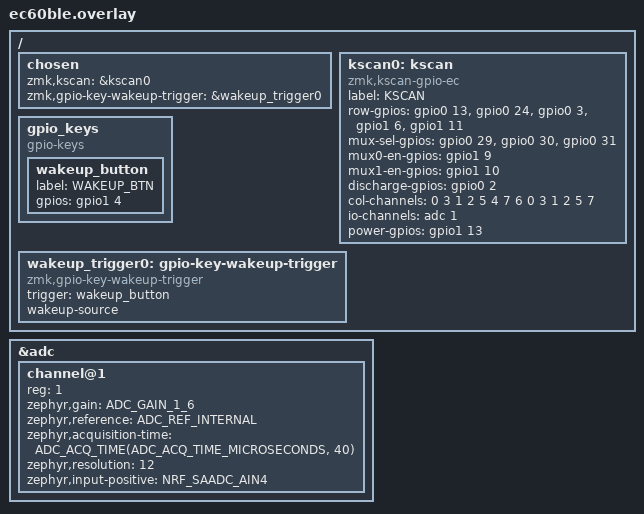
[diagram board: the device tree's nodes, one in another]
/*
 * Copyright (c) 2023 ssbb
 *
 * SPDX-License-Identifier: MIT
 */


#include "ec60ble.dtsi"

/ {
  
  chosen {
    zmk,kscan = &kscan0;
    zmk,gpio-key-wakeup-trigger = &wakeup_trigger0;
    /* zephyr,console = &uart0; */
  };

    /* &gpio0 13 -> P0.13  (ROW 0)*/
    /* &gpio0 24 -> P0.24  (ROW 1)*/
    /* &gpio0 3 -> P0.03  (ROW 2)*/
    /* &gpio1 6 -> P1.06  (ROW 3)*/
    /* &gpio1 11 -> P1.11  (ROW 4)*/

  kscan0: kscan {
    compatible = "zmk,kscan-gpio-ec";
    label = "KSCAN";

    row-gpios
    = <&gpio0 13 GPIO_ACTIVE_HIGH>
    , <&gpio0 24 GPIO_ACTIVE_HIGH>
    , <&gpio0 3 GPIO_ACTIVE_HIGH>
    , <&gpio1 6 GPIO_ACTIVE_HIGH>
    , <&gpio1 11 GPIO_ACTIVE_HIGH>
    ;

    // mux select gpios for selecting which col channel to scan
    mux-sel-gpios
    = <&gpio0 29 GPIO_ACTIVE_HIGH>
    , <&gpio0 30 GPIO_ACTIVE_HIGH>
    , <&gpio0 31 GPIO_ACTIVE_HIGH>
    ;

    // 2 multiplexer enable pins in col number ascending order
    mux0-en-gpios = <&gpio1 9 GPIO_ACTIVE_HIGH>;

    mux1-en-gpios = <&gpio1 10 GPIO_ACTIVE_HIGH>;

    discharge-gpios = <&gpio0 2 GPIO_ACTIVE_HIGH>;

    /* 2 multiplexer pin number mapping to all channels from #0-14 */
    col-channels = <0 3 1 2 5 4 7 6 0 3 1 2 5 7>;
    io-channels = <&adc 1>;
    power-gpios = <&gpio1 13 GPIO_ACTIVE_HIGH>;
    /* mask unused position in each row */
    // row-input-masks = <(BIT(13)) 0 (BIT(13)) (BIT(11)) (BIT(3) + BIT(5) + BIT(6) + BIT(7) + BIT(9) + BIT(10) + BIT(11) + BIT(12) + BIT(13))>;
  };


  gpio_keys {
    compatible = "gpio-keys";
    wakeup_button: wakeup_button {
    label = "WAKEUP_BTN";
    gpios = <&gpio1 4 GPIO_ACTIVE_HIGH>; // wake up pin GPIO1 pin 4
    };
  };

  wakeup_trigger0: gpio-key-wakeup-trigger {
    compatible = "zmk,gpio-key-wakeup-trigger";   /* Use ZMK's GPIO key wakeup driver */
    trigger = <&wakeup_button>;    /* Reference the wakeup_button node's phandle  */
    wakeup-source;    /* Mark this device as able to wake the keyboard */
  };
};

&adc {
  #address-cells = <1>;
  #size-cells = <0>;
  status = "okay";

  // EC Read
  channel@1 {
    reg = <1>;
    zephyr,gain = "ADC_GAIN_1_6";
    zephyr,reference = "ADC_REF_INTERNAL";
    zephyr,acquisition-time = <ADC_ACQ_TIME(ADC_ACQ_TIME_MICROSECONDS, 40)>;
    zephyr,resolution = <12>;
    zephyr,input-positive = <NRF_SAADC_AIN4>; /* P0.28 */
  };

  // Battery Sensing
  /* channel@3 {
   * reg = <3>;
   * zephyr,gain = "ADC_GAIN_1_6";
   * zephyr,reference = "ADC_REF_INTERNAL";
   * zephyr,acquisition-time = <ADC_ACQ_TIME(ADC_ACQ_TIME_MICROSECONDS, 40)>;
   * zephyr,resolution = <12>;
   * zephyr,input-positive = <NRF_SAADC_AIN5>;
   * };
   */
};

/*
 * &uart0 {
 *   status = "okay";
 *   current-speed = <115200>;
 * };
 */
